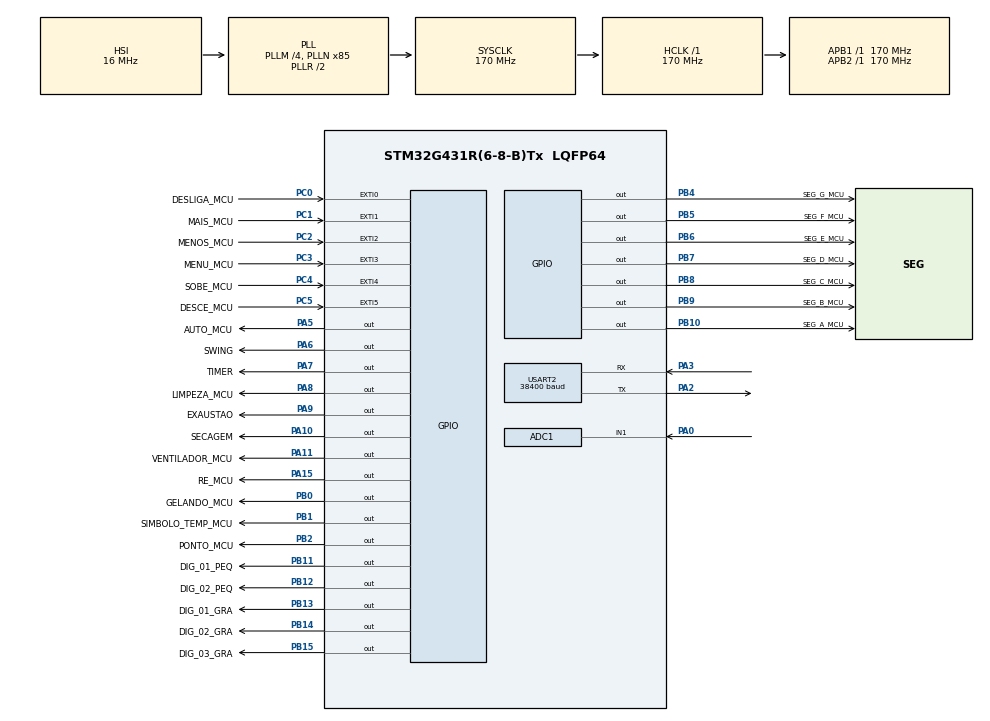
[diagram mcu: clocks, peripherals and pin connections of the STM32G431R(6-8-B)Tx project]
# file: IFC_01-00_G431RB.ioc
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ADC1.Channel-0\#ChannelRegularConversion=ADC_CHANNEL_1
ADC1.NbrOfConversionFlag=1
ADC1.OffsetNumber-0\#ChannelRegularConversion=ADC_OFFSET_NONE
ADC1.Rank-0\#ChannelRegularConversion=1
ADC1.SamplingTime-0\#ChannelRegularConversion=ADC_SAMPLETIME_2CYCLES_5
ADC1.master=1
Mcu.Family=STM32G4
Mcu.Name=STM32G431R(6-8-B)Tx
Mcu.Package=LQFP64
NVIC.PriorityGroup=NVIC_PRIORITYGROUP_4
NVIC.TIM7_IRQn=true\:5\:0\:true\:false\:true\:true\:true\:true
NVIC.USART2_IRQn=true\:6\:0\:true\:false\:true\:true\:true\:true
PA0.Mode=IN1-Single-Ended
PA0.Signal=ADC1_IN1
PA10.GPIO_Label=SECAGEM
PA10.Signal=GPIO_Output
PA11.GPIO_Label=VENTILADOR_MCU
PA11.Signal=GPIO_Output
PA13.Mode=Serial_Wire
PA13.Signal=SYS_JTMS-SWDIO
PA14.Mode=Serial_Wire
PA14.Signal=SYS_JTCK-SWCLK
PA15.GPIO_Label=RE_MCU
PA15.Signal=GPIO_Output
PA2.Mode=Asynchronous
PA2.Signal=USART2_TX
PA3.Mode=Asynchronous
PA3.Signal=USART2_RX
PA5.GPIO_Label=AUTO_MCU
PA5.Signal=GPIO_Output
PA6.GPIO_Label=SWING
PA6.Signal=GPIO_Output
PA7.GPIO_Label=TIMER
PA7.Signal=GPIO_Output
PA8.GPIO_Label=LIMPEZA_MCU
PA8.Signal=GPIO_Output
PA9.GPIO_Label=EXAUSTAO
PA9.Signal=GPIO_Output
PB0.GPIO_Label=GELANDO_MCU
PB0.Signal=GPIO_Output
PB1.GPIO_Label=SIMBOLO_TEMP_MCU
PB1.Signal=GPIO_Output
PB10.GPIO_Label=SEG_A_MCU
PB10.Signal=GPIO_Output
PB11.GPIO_Label=DIG_01_PEQ
PB11.Signal=GPIO_Output
PB12.GPIO_Label=DIG_02_PEQ
PB12.Signal=GPIO_Output
PB13.GPIO_Label=DIG_01_GRA
PB13.Signal=GPIO_Output
PB14.GPIO_Label=DIG_02_GRA
PB14.Signal=GPIO_Output
PB15.GPIO_Label=DIG_03_GRA
PB15.Signal=GPIO_Output
PB2.GPIO_Label=PONTO_MCU
PB2.Signal=GPIO_Output
PB4.GPIO_Label=SEG_G_MCU
PB4.Signal=GPIO_Output
PB5.GPIO_Label=SEG_F_MCU
PB5.Signal=GPIO_Output
PB6.GPIO_Label=SEG_E_MCU
PB6.Signal=GPIO_Output
PB7.GPIO_Label=SEG_D_MCU
PB7.Signal=GPIO_Output
PB8-BOOT0.GPIO_Label=SEG_C_MCU
PB8-BOOT0.Signal=GPIO_Output
PB9.GPIO_Label=SEG_B_MCU
PB9.Signal=GPIO_Output
PC0.GPIO_Label=DESLIGA_MCU
PC0.GPIO_PuPd=GPIO_PULLUP
PC0.Signal=GPXTI0
PC1.GPIO_Label=MAIS_MCU
PC1.GPIO_PuPd=GPIO_PULLUP
PC1.Signal=GPXTI1
PC2.GPIO_Label=MENOS_MCU
PC2.GPIO_PuPd=GPIO_PULLUP
PC2.Signal=GPXTI2
PC3.GPIO_Label=MENU_MCU
PC3.GPIO_PuPd=GPIO_PULLUP
PC3.Signal=GPXTI3
PC4.GPIO_Label=SOBE_MCU
PC4.GPIO_PuPd=GPIO_PULLUP
PC4.Signal=GPXTI4
PC5.GPIO_Label=DESCE_MCU
PC5.GPIO_PuPd=GPIO_PULLUP
PC5.Signal=GPXTI5
ProjectManager.HeapSize=0x200
ProjectManager.StackSize=0x400
ProjectManager.TargetToolchain=STM32CubeIDE
RCC.ADC12Freq_Value=170000000
RCC.AHBFreq_Value=170000000
RCC.APB1Freq_Value=170000000
RCC.APB1TimFreq_Value=170000000
RCC.APB2Freq_Value=170000000
RCC.APB2TimFreq_Value=170000000
RCC.CortexFreq_Value=170000000
RCC.EXTERNAL_CLOCK_VALUE=12288000
RCC.HCLKFreq_Value=170000000
RCC.HSE_VALUE=8000000
RCC.HSI48_VALUE=48000000
RCC.HSI_VALUE=16000000
RCC.LSE_VALUE=32768
RCC.PLLM=RCC_PLLM_DIV4
RCC.PLLN=85
RCC.SYSCLKFreq_VALUE=170000000
RCC.SYSCLKSource=RCC_SYSCLKSOURCE_PLLCLK
RCC.USBFreq_Value=170000000
RCC.VCOOutputFreq_Value=340000000
TIM7.PeriodNoDither=99
TIM7.Prescaler=169
USART2.BaudRate=38400
USART2.VirtualMode-Asynchronous=VM_ASYNC
VP_SYS_VS_DBSignals.Mode=DisableDeadBatterySignals
VP_TIM7_VS_ClockSourceINT.Mode=Enable_Timer
board=custom

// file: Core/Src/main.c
/* USER CODE BEGIN Header */
/**
  ******************************************************************************
  * @file           : main.c
  * @brief          : Main program body
  ******************************************************************************
  * @attention
  *
  * Copyright (c) 2026 STMicroelectronics.
  * All rights reserved.
  *
  * This software is licensed under terms that can be found in the LICENSE file
  * in the root directory of this software component.
  * If no LICENSE file comes with this software, it is provided AS-IS.
  *
  ******************************************************************************
  */
/* USER CODE END Header */
#include "main.h"
#include "adc.h"
#include "tim.h"
#include "usart.h"
#include "gpio.h"

/* USER CODE BEGIN Includes */
#include "app.h"
/* USER CODE END Includes */

/* USER CODE BEGIN PV */
app_t app = {0};
/* USER CODE END PV */

void SystemClock_Config(void);

int main(void)
{

  /* MCU Configuration--------------------------------------------------------*/

  /* Reset of all peripherals, Initializes the Flash interface and the Systick. */
  HAL_Init();

  /* Configure the system clock */
  SystemClock_Config();

  /* Initialize all configured peripherals */
  MX_GPIO_Init();
  MX_ADC1_Init();
  MX_USART2_UART_Init();
  MX_TIM7_Init();

  /* Infinite loop */
  /* USER CODE BEGIN WHILE */
  app_run(&app);
  while (1)
  {
    /* USER CODE END WHILE */

  }
}

void SystemClock_Config(void)
{
  RCC_OscInitTypeDef RCC_OscInitStruct = {0};
  RCC_ClkInitTypeDef RCC_ClkInitStruct = {0};

  /** Configure the main internal regulator output voltage
  */
  HAL_PWREx_ControlVoltageScaling(PWR_REGULATOR_VOLTAGE_SCALE1_BOOST);

  /** Initializes the RCC Oscillators according to the specified parameters
  * in the RCC_OscInitTypeDef structure.
  */
  RCC_OscInitStruct.OscillatorType = RCC_OSCILLATORTYPE_HSI;
  RCC_OscInitStruct.HSIState = RCC_HSI_ON;
  RCC_OscInitStruct.HSICalibrationValue = RCC_HSICALIBRATION_DEFAULT;
  RCC_OscInitStruct.PLL.PLLState = RCC_PLL_ON;
  RCC_OscInitStruct.PLL.PLLSource = RCC_PLLSOURCE_HSI;
  RCC_OscInitStruct.PLL.PLLM = RCC_PLLM_DIV4;
  RCC_OscInitStruct.PLL.PLLN = 85;
  RCC_OscInitStruct.PLL.PLLP = RCC_PLLP_DIV2;
  RCC_OscInitStruct.PLL.PLLQ = RCC_PLLQ_DIV2;
  RCC_OscInitStruct.PLL.PLLR = RCC_PLLR_DIV2;
  if (HAL_RCC_OscConfig(&RCC_OscInitStruct) != HAL_OK)
  {
    Error_Handler();
  }

  /** Initializes the CPU, AHB and APB buses clocks
  */
  RCC_ClkInitStruct.ClockType = RCC_CLOCKTYPE_HCLK|RCC_CLOCKTYPE_SYSCLK
                              |RCC_CLOCKTYPE_PCLK1|RCC_CLOCKTYPE_PCLK2;
  RCC_ClkInitStruct.SYSCLKSource = RCC_SYSCLKSOURCE_PLLCLK;
  RCC_ClkInitStruct.AHBCLKDivider = RCC_SYSCLK_DIV1;
  RCC_ClkInitStruct.APB1CLKDivider = RCC_HCLK_DIV1;
  RCC_ClkInitStruct.APB2CLKDivider = RCC_HCLK_DIV1;

  if (HAL_RCC_ClockConfig(&RCC_ClkInitStruct, FLASH_LATENCY_4) != HAL_OK)
  {
    Error_Handler();
  }
}

void Error_Handler(void)
{
  __disable_irq();
  while (1)
  {
  }
}
